AUTOSAR XML (schema 00046)
package /ComponentTypes
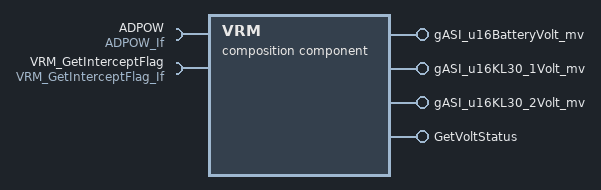
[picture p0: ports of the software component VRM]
  composition sw component type VRM
    4 x provide port:
      gASI_u16BatteryVolt_mv: nonqueued-sender-com-spec=Val, provided-interface=gASI_u16BatteryVolt_mv
      gASI_u16KL30_1Volt_mv: nonqueued-sender-com-spec=Val, provided-interface=gASI_u16KL30_1Volt_mv
      gASI_u16KL30_2Volt_mv: nonqueued-sender-com-spec=Val, provided-interface=gASI_u16KL30_2Volt_mv
      GetVoltStatus: server-com-spec{operation=Operation, queue-length=1}, provided-interface=GetVoltStatus
    require port ADPOW: required-interface=ADPOW_If
      required-com-specs:
        data-element=AD_KL30_1_FV, filter=data-filter-type=ALWAYS
        data-element=AD_VPUP1_FV, filter=data-filter-type=ALWAYS
        data-element=AD_VPUP2_FV, filter=data-filter-type=ALWAYS
        data-element=AD_KL30_2_FV, filter=data-filter-type=ALWAYS
        data-element=AD_VPUP3_FV, filter=data-filter-type=ALWAYS
        data-element=AD_SLC_POWER_FV, filter=data-filter-type=ALWAYS
    require port VRM_GetInterceptFlag: client-com-spec=Operation, required-interface=VRM_GetInterceptFlag_If
    component VRM_InputsReading: type=VRM_InputsReading
    component VRM_VoltSts: type=VRM_VoltSts
    connect VRM_InputsReading.gVRM_u16VBatADValue -> VRM_VoltSts.gVRM_u16VBatADValue
    delegate VRM_InputsReading.ADPOW <-> outer port ADPOW
    delegate VRM_InputsReading.gASI_u16BatteryVolt_mv <-> outer port gASI_u16BatteryVolt_mv
    delegate VRM_InputsReading.gASI_u16KL30_1Volt_mv <-> outer port gASI_u16KL30_1Volt_mv
    delegate VRM_InputsReading.gASI_u16KL30_2Volt_mv <-> outer port gASI_u16KL30_2Volt_mv
    delegate VRM_VoltSts.GetVoltStatus <-> outer port GetVoltStatus
    delegate VRM_VoltSts.VRM_GetInterceptFlag <-> outer port VRM_GetInterceptFlag
